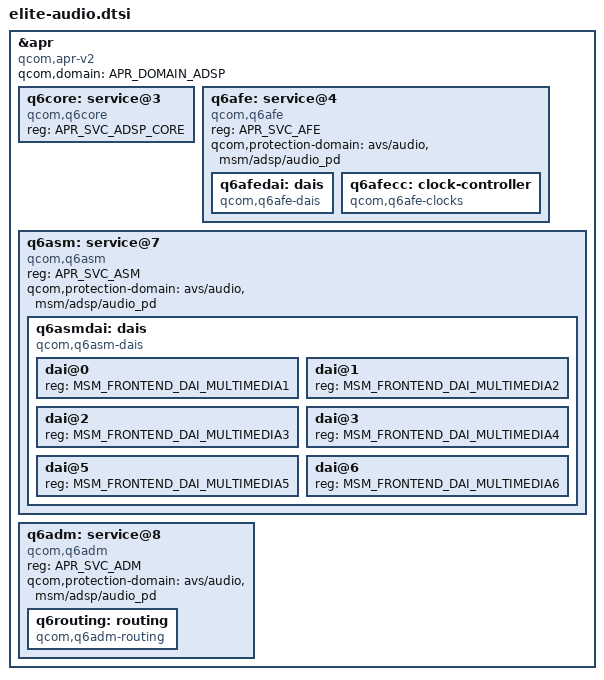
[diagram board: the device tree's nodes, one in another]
// SPDX-License-Identifier: (GPL-2.0+ OR BSD-3-Clause)
/*
 * Copyright (c) 2025 Qualcomm Innovation Center, Inc. All rights reserved.
 */

#include <dt-bindings/soc/qcom,apr.h>
#include <dt-bindings/sound/qcom,q6asm.h>
#include <dt-bindings/sound/qcom,q6dsp-lpass-ports.h>

&apr {
	compatible = "qcom,apr-v2";
	qcom,domain = <APR_DOMAIN_ADSP>;
	#address-cells = <1>;
	#size-cells = <0>;

	q6core: service@3 {
		compatible = "qcom,q6core";
		reg = <APR_SVC_ADSP_CORE>;
	};

	q6afe: service@4 {
		compatible = "qcom,q6afe";
		reg = <APR_SVC_AFE>;
		qcom,protection-domain = "avs/audio", "msm/adsp/audio_pd";

		q6afedai: dais {
			compatible = "qcom,q6afe-dais";
			#address-cells = <1>;
			#size-cells = <0>;
			#sound-dai-cells = <1>;
		};

		q6afecc: clock-controller {
			compatible = "qcom,q6afe-clocks";
			#clock-cells = <2>;
		};

	};

	q6asm: service@7 {
		compatible = "qcom,q6asm";
		reg = <APR_SVC_ASM>;
		qcom,protection-domain = "avs/audio", "msm/adsp/audio_pd";

		q6asmdai: dais {
			compatible = "qcom,q6asm-dais";
			#address-cells = <1>;
			#size-cells = <0>;
			#sound-dai-cells = <1>;
			dai@0 {
				reg = <MSM_FRONTEND_DAI_MULTIMEDIA1>;
			};

			dai@1 {
				reg = <MSM_FRONTEND_DAI_MULTIMEDIA2>;
			};

			dai@2 {
				reg = <MSM_FRONTEND_DAI_MULTIMEDIA3>;
			};

			dai@3 {
				reg = <MSM_FRONTEND_DAI_MULTIMEDIA4>;
			};

			dai@5 {
				reg = <MSM_FRONTEND_DAI_MULTIMEDIA5>;
			};

			dai@6 {
				reg = <MSM_FRONTEND_DAI_MULTIMEDIA6>;
			};
		};
	};

	q6adm: service@8 {
		compatible = "qcom,q6adm";
		reg = <APR_SVC_ADM>;
		qcom,protection-domain = "avs/audio", "msm/adsp/audio_pd";

		q6routing: routing {
			compatible = "qcom,q6adm-routing";
			#sound-dai-cells = <0>;
		};
	};
};
